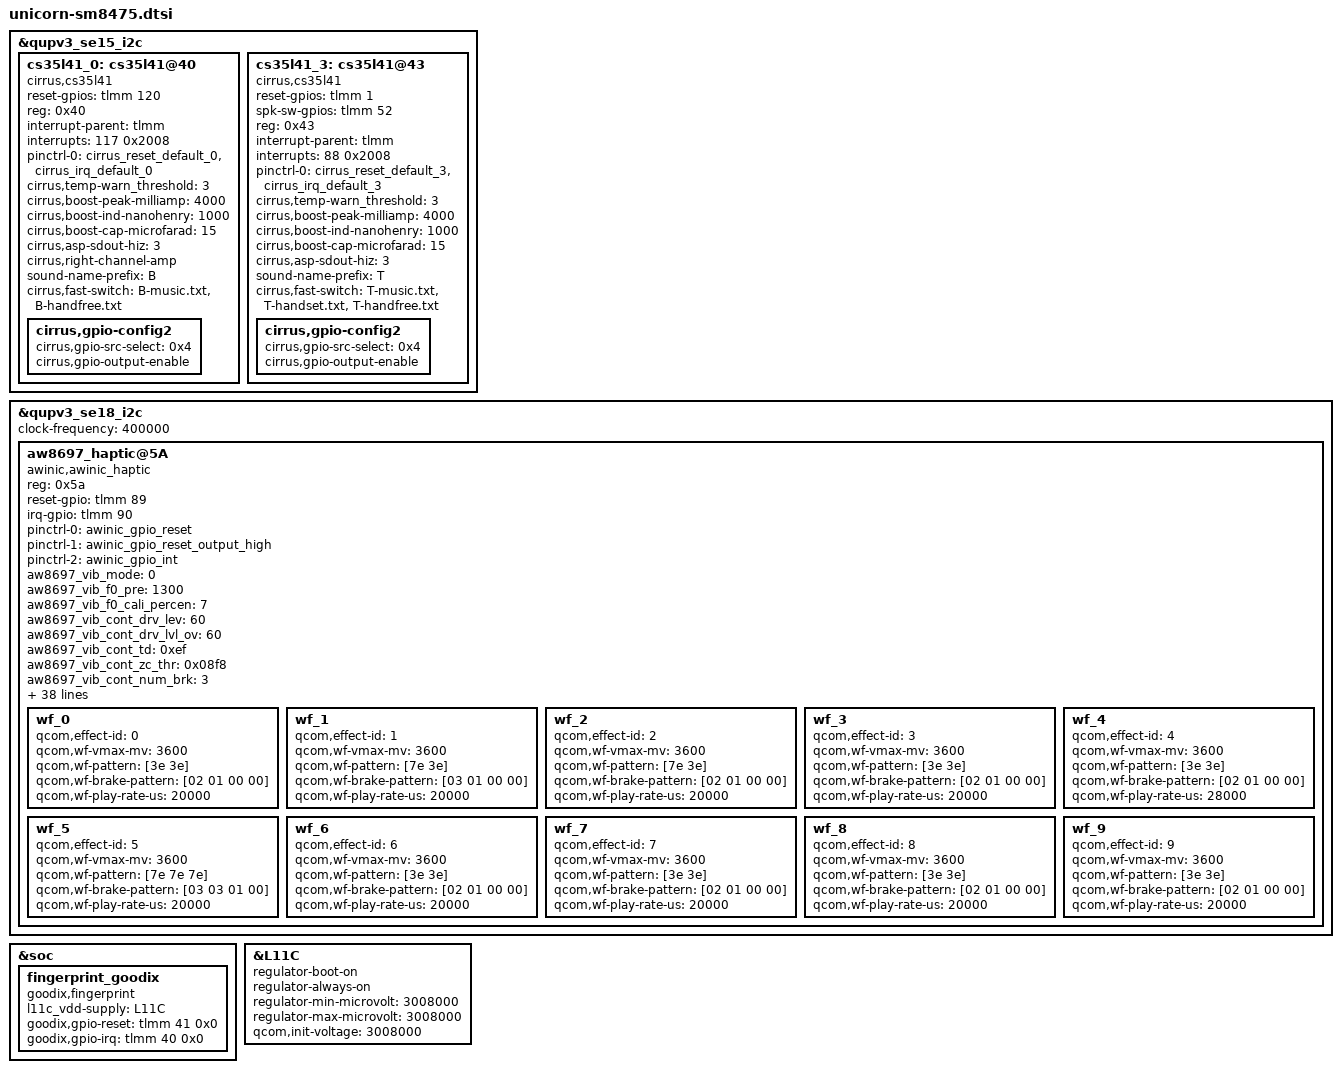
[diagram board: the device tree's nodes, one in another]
/*
   this file is for attribution only of unicorn
   And public attribution of xiaomi platforms(like K2 and so and)
*/
#include "unicorn-pinctrl.dtsi"
#include "xiaomi-sm8475-common.dtsi"

&qupv3_se15_i2c {
	status = "ok";
	cs35l41_0: cs35l41@40 {
		status = "ok";
		compatible = "cirrus,cs35l41";
		reset-gpios = <&tlmm 120 0>;
		reg = <0x40>;
		interrupt-parent = <&tlmm>;
		interrupts = <117 0x2008>;
		pinctrl-names = "default";
		pinctrl-0 = <&cirrus_reset_default_0 &cirrus_irq_default_0>;
		cirrus,temp-warn_threshold = <3>;
		cirrus,boost-peak-milliamp = <4000>;
		cirrus,boost-ind-nanohenry = <1000>;
		cirrus,boost-cap-microfarad = <15>;
		cirrus,asp-sdout-hiz = <3>;
		cirrus,right-channel-amp;
		sound-name-prefix = "B";
		cirrus,fast-switch = "B-music.txt", "B-handfree.txt";
		cirrus,gpio-config2 {
			cirrus,gpio-src-select = <0x4>;
			cirrus,gpio-output-enable;
		};
	};
	cs35l41_3: cs35l41@43 {
		status = "ok";
		compatible = "cirrus,cs35l41";
		reset-gpios = <&tlmm 1 0>;
		spk-sw-gpios = <&tlmm 52 0>;
		reg = <0x43>;
		interrupt-parent = <&tlmm>;
		interrupts = <88 0x2008>;
		pinctrl-names = "default";
		pinctrl-0 = <&cirrus_reset_default_3 &cirrus_irq_default_3>;
		cirrus,temp-warn_threshold = <3>;
		cirrus,boost-peak-milliamp = <4000>;
		cirrus,boost-ind-nanohenry = <1000>;
		cirrus,boost-cap-microfarad = <15>;
		cirrus,asp-sdout-hiz = <3>;
		sound-name-prefix = "T";
		cirrus,fast-switch = "T-music.txt", "T-handset.txt", "T-handfree.txt";
		cirrus,gpio-config2 {
			cirrus,gpio-src-select = <0x4>;
			cirrus,gpio-output-enable;
		};
	};
};

&qupv3_se18_i2c {
	#address-cells = <1>;
	#size-cells = <0>;
	clock-frequency = <400000>;
	status = "ok";
	aw8697_haptic@5A {
		compatible = "awinic,awinic_haptic";
		reg = <0x5a>;
		reset-gpio = <&tlmm 89 0x00>;
		irq-gpio = <&tlmm 90 0x00>;
		pinctrl-names = "awinic_reset_reset","awinic_reset_active","awinic_interrupt_active";
		pinctrl-0 = <&awinic_gpio_reset>;
		pinctrl-1 = <&awinic_gpio_reset_output_high>;
		pinctrl-2 = <&awinic_gpio_int>;
		/*----------------------aw8697----------------------*/
		aw8697_vib_mode = < 0 >; /*mode:   RAM mode->0; CONT mode -> 1*/
		aw8697_vib_f0_pre = < 1300 >;
		aw8697_vib_f0_cali_percen = < 7 >;
		aw8697_vib_cont_drv_lev = < 60 >;
		aw8697_vib_cont_drv_lvl_ov = < 60 >;
		aw8697_vib_cont_td = < 0xef >;
		aw8697_vib_cont_zc_thr = < 0x08f8 >;  /*hq 0x08F8 */
		aw8697_vib_cont_num_brk = < 3 >;
		aw8697_vib_f0_coeff = < 260 >; /*Don't modify it 2.604167*/
		aw8697_vib_f0_trace_parameter = < 9 3 1 31 >;
		aw8697_vib_bemf_config = < 0 0x08 0x03 0xf8 >;
		aw8697_vib_sw_brake = < 0x2c >;
		aw8697_vib_tset = < 0x1a >;
		aw8697_vib_r_spare = < 0x68 >;
		aw8697_vib_bstdbg = < 0x30 0xeb 0xd4 0 0 0 >;
		aw8697_vib_trig_config = < 0 1 0 1 2
					   0 1 0 1 2
					   0 1 0 1 2 >;
		aw8697_vib_bst_vol_default = < 0x0e >;
		aw8697_vib_bst_vol_ram = < 0x0e >;
		aw8697_vib_bst_vol_rtp = < 0x0e >;
		/*----------------------aw8692x----------------------*/
		aw86927_vib_mode = < 0 >; /* mode: RAM mode->0; CONT mode->1 */
		aw86927_vib_f0_pre = < 1300 >;
		aw86927_vib_f0_cali_percen = < 7 >;
		aw86927_vib_cont_drv1_lvl = < 0x7F >;
		aw86927_vib_cont_drv2_lvl = < 0x36 >;
		aw86927_vib_cont_drv1_time = < 0x04 >;
		aw86927_vib_cont_drv2_time = < 0x06 >;
		aw86927_vib_cont_drv_width = < 0x6A >;
		aw86927_vib_cont_wait_num = < 0x06 >;
		aw86927_vib_cont_brk_time = < 0x08 >;
		aw86927_vib_cont_track_margin = < 0x0C >;
		aw86927_vib_brk_bst_md = < 0 >;
		aw86927_vib_cont_tset = < 0x06 >;
		aw86927_vib_cont_bemf_set = < 0x02 >;
		aw86927_vib_cont_bst_brk_gain = < 0x05 >;
		aw86927_vib_cont_brk_gain = < 0x08 >;
		aw86927_vib_d2s_gain = < 0x04 >;
		aw86927_vib_trig_config = < 0 0 0 1 0 2 0 0
					    0 0 0 1 0 2 0 0
					    0 0 0 1 0 2 0 0 >;
		aw86927_vib_bst_vol_default = < 0x5F >;
		aw86927_vib_bst_vol_ram = < 0x5F >;
		aw86927_vib_bst_vol_rtp = < 0x5F >;
		/*--------------------common--------------------*/
		vib_effect_id_boundary = < 10 >;
		vib_effect_max = < 197 >; /*vib_effect_max must bigger than vib_effect_id*/
		vib_rtp_time = < 20 20 20 20 20 20 20 20 20000 15000
				15000 20000 25000 15000 30000 25000 20000 20000 20000 20000
				20000 20000 20000 20000 20000 20000 20000 20000 20000 20000
				20000 20000 20000 20000 20000 20000 20000 20000 20000 20000
				20000 20000 20000 20000 20000 20000 20000 20000 20000 20000
				20000 20000 20000 20000 20000 20000 20000 20000 20000 20000
				20000 20000 20000 20000 20000 20000 20000 20000 20000 20000
				20000 20000 20000 20000 20000 20000 20000 20000 20000 20000
				20000 20000 20000 20000 20000 20000 20000 20000 20000 20000
				20000 20000 20000 20000 20000 20000 20000 20000 20000 20000
				20000 20000 20000 20000 20000 20000 20000 20000 20000 20000
				20000 20000 20000 20000 20000 20000 20000 20000 20000 20000
				20000 20000 20000 20000 20000 20000 20000 20000 20000 20000
				20000 20000 20000 20000 20000 20000 20000 20000 20000 20000
				20000 20000 20000 20000 20000 20000 20000 20000 20000 20000
				20000 20000 20000 20000 20000 20000 20000 20000 20000 20000
				20000 20000 20000 20000 20000 20000 20000 20000 20000 20000
				20000 20000 20000 20000 20000 >;
		status = "ok";
		wf_0 {
			/*CLICK*/
			qcom,effect-id = <0>;
			qcom,wf-vmax-mv = <3600>;
			qcom,wf-pattern = [3e 3e];
			qcom,wf-brake-pattern = [02 01 00 00];
			qcom,wf-play-rate-us = <20000>;
		};
		wf_1 {
			/*DOUBLE CLICK*/
			qcom,effect-id = <1>;
			qcom,wf-vmax-mv = <3600>;
			qcom,wf-pattern = [7e 3e];
			qcom,wf-brake-pattern = [03 01 00 00];
			qcom,wf-play-rate-us = <20000>;
		};
		wf_2 {
			/*TICK*/
			qcom,effect-id = <2>;
			qcom,wf-vmax-mv = <3600>;
			qcom,wf-pattern = [7e 3e];
			qcom,wf-brake-pattern = [02 01 00 00];
			qcom,wf-play-rate-us = <20000>;
		};
		wf_3 {
			/*THUD*/
			qcom,effect-id = <3>;
			qcom,wf-vmax-mv = <3600>;
			qcom,wf-pattern = [3e 3e];
			qcom,wf-brake-pattern = [02 01 00 00];
			qcom,wf-play-rate-us = <20000>;
		};
		wf_4 {
			/*POP*/
			qcom,effect-id = <4>;
			qcom,wf-vmax-mv = <3600>;
			qcom,wf-pattern = [3e 3e];
			qcom,wf-brake-pattern = [02 01 00 00];
			qcom,wf-play-rate-us = <28000>;
		};
		wf_5 {
			/*HEAVY CLICK*/
			qcom,effect-id = <5>;
			qcom,wf-vmax-mv = <3600>;
			qcom,wf-pattern = [7e 7e 7e];
			qcom,wf-brake-pattern = [03 03 01 00];
			qcom,wf-play-rate-us = <20000>;
		};
		wf_6 {
			/*id 6*/
			qcom,effect-id = <6>;
			qcom,wf-vmax-mv = <3600>;
			qcom,wf-pattern = [3e 3e];
			qcom,wf-brake-pattern = [02 01 00 00];
			qcom,wf-play-rate-us = <20000>;
		};
		wf_7 {
			/*id 7*/
			qcom,effect-id = <7>;
			qcom,wf-vmax-mv = <3600>;
			qcom,wf-pattern = [3e 3e];
			qcom,wf-brake-pattern = [02 01 00 00];
			qcom,wf-play-rate-us = <20000>;
		};
		wf_8 {
			/*id 8*/
			qcom,effect-id = <8>;
			qcom,wf-vmax-mv = <3600>;
			qcom,wf-pattern = [3e 3e];
			qcom,wf-brake-pattern = [02 01 00 00];
			qcom,wf-play-rate-us = <20000>;
		};
		wf_9 {
			/*id 9*/
			qcom,effect-id = <9>;
			qcom,wf-vmax-mv = <3600>;
			qcom,wf-pattern = [3e 3e];
			qcom,wf-brake-pattern = [02 01 00 00];
			qcom,wf-play-rate-us = <20000>;
		};
	};
};

&soc {
        fingerprint_goodix {
		compatible = "goodix,fingerprint";
		l11c_vdd-supply = <&L11C>;
		goodix,gpio-reset = <&tlmm 41 0x0>;
		goodix,gpio-irq = <&tlmm 40 0x0>;
		status = "ok";
	};
};

&L11C {
	regulator-boot-on;
	regulator-always-on;
	regulator-min-microvolt = <3008000>;
	regulator-max-microvolt = <3008000>;
	qcom,init-voltage = <3008000>;
};

